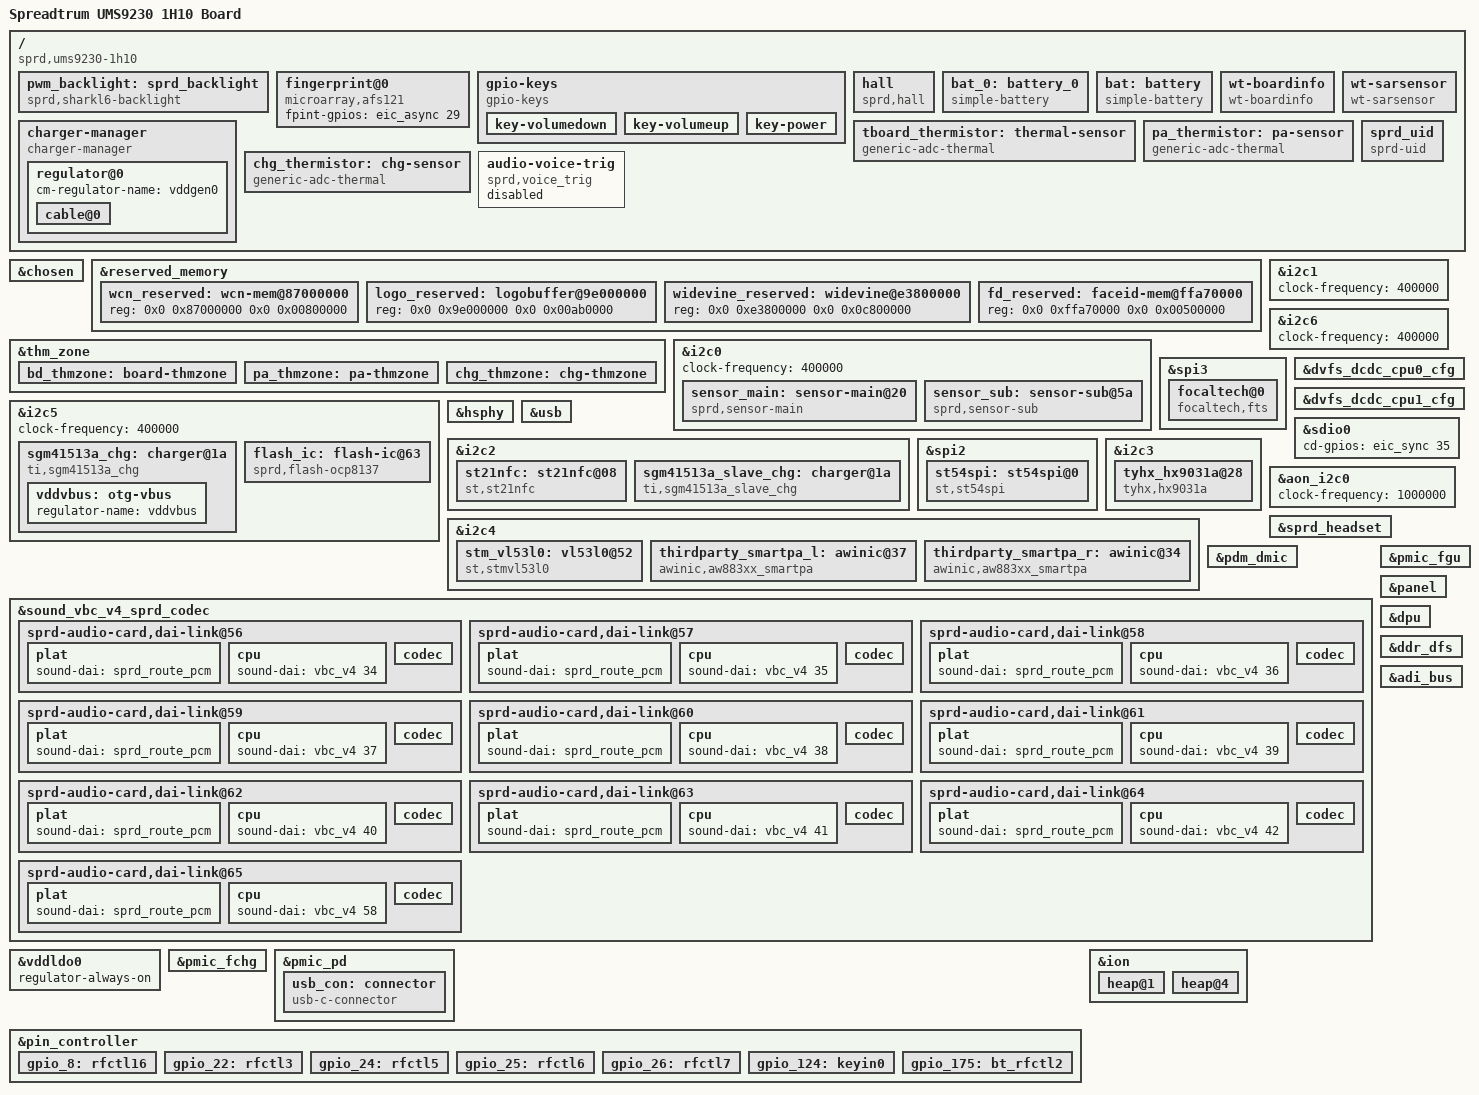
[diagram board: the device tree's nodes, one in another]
/dts-v1/;
/plugin/;
#include <dt-bindings/input/input.h>
#include <dt-bindings/gpio/gpio.h>
#include <dt-bindings/interrupt-controller/arm-gic.h>
#include <dt-bindings/clock/sprd,ums9230-clk.h>
#include <dt-bindings/mfd/sprd,sc2730-regs.h>
#include <dt-bindings/mfd/sprd,sc2730-mask.h>
#include <dt-bindings/usb/pd.h>
//#include "lcd/lcd_g40396_truly_mipi_fhd.dtsi"
//#include "lcd/lcd_dummy_mipi.dtsi"
#include "lcd/lcd_BL_TA4RUS07VOFMZTB_mipi_fhd.dtsi"
#include "TP/novatek-nt36xxx-spi.dtsi"
#include "ums9230-wcn.dtsi"

/ {

	model = "Spreadtrum UMS9230 1H10 Board";

	compatible = "sprd,ums9230-1h10";

	sprd,sc-id = "ums9230 1h10 1000";
	fragment {
		target-path = "/";
		__overlay__ {
			pwm_backlight: sprd_backlight {
				compatible = "sprd,sharkl6-backlight";
				pwms = <&pwms 2 40000>;
				pwm-names = "backlight";
				sprd,max-brightness-level = <924>;
				default-brightness-level = <262>;
				//sprd,brightness-scale = <1023>;
				brightness-levels = <
							              0   8   8   9  10  10 
                         11  12  13  13  14  15  16  17  18  19 
                         20  21  22  23  24  25  26  27  28  29 
                         30  32  33  34  35  37  38  39  41  42 
                         44  45  47  48  50  51  53  54  56  58 
                         59  61  63  64  66  68  70  71  73  75 
                         77  79  81  83  85  87  89  91  93  95 
                         97  99 102 104 106 108 111 113 115 118 
                        120 122 125 127 130 132 135 137 140 142 
                        145 147 150 153 155 158 161 164 167 169 
                        172 175 178 181 184 187 190 193 196 199 
                        202 205 208 211 214 218 221 224 227 231 
                        234 237 241 244 247 251 254 258 261 265 
                        268 272 275 279 283 286 290 294 297 301 
                        305 309 313 316 320 324 328 332 336 340 
                        344 348 352 356 360 364 369 373 377 381 
                        386 390 394 398 403 407 412 416 420 425 
                        429 434 438 443 448 452 457 461 466 471 
                        476 480 485 490 495 499 504 509 514 519 
                        524 529 534 539 544 549 554 559 565 570 
                        575 580 585 591 596 601 607 612 617 623 
                        628 634 639 645 650 656 661 667 672 678 
                        684 689 695 701 707 712 718 724 730 736 
                        742 748 754 760 766 772 778 784 790 796 
                        802 808 814 821 827 833 839 846 852 858 
                        865 871 877 884 890 897 903 910 917 924
				>;
			};

			fingerprint@0 {
				compatible = "microarray,afs121";
				fpint-gpios = <&eic_async 29 0>;
			};

			gpio-keys {
				compatible = "gpio-keys";

				key-volumedown {
					label = "Volume Down Key";
					linux,code = <KEY_VOLUMEDOWN>;
					gpios = <&pmic_eic 4 GPIO_ACTIVE_HIGH>;
					debounce-interval = <2>;
					wakeup-source;
				};

				key-volumeup {
					label = "Volume Up Key";
					linux,code = <KEY_VOLUMEUP>;
					gpios = <&ap_gpio 124 GPIO_ACTIVE_LOW>;					
					debounce-interval = <2>;
					wakeup-source;
				};

				key-power {
					label = "Power Key";
					linux,code = <KEY_POWER>;
					gpios = <&pmic_eic 1 GPIO_ACTIVE_LOW>;
					debounce-interval = <2>;
					wakeup-source;
				};
			};
			
            hall {
                    compatible = "sprd,hall";
                    gpio_det_level_pin = <&ap_gpio 122 GPIO_ACTIVE_LOW>;
                    status = "okay";
            };
			
			bat_0: battery_0 {
				compatible = "simple-battery";
				charge-full-design-microamp-hours = <8205000>;
				charge-term-current-microamp = <200000>;
				constant-charge-voltage-max-microvolt = <4432000>;
				fullbatt-voltage-offset-microvolt = <45000>;
				factory-internal-resistance-micro-ohms = <92000>;
				voltage-min-design-microvolt = <3450000>;
				fullbatt-voltage = <4340000>;
				fullbatt-current = <200000>;
				fullbatt-track-end-vol = <4345000>;
				fullbatt-track-end-cur = <130000>;
				first-calib-voltage = <3630000>;
				first-calib-capacity = <50>;

				ocv-capacity-celsius = <20>;
				ocv-capacity-table-0 = <4366000 100>, <4310000 95>, <4253000 90>,
							<4197000 85>, <4143000 80>, <4090000 75>,
							<4044000 70>, <3992000 65>, <3953000 60>,
							<3895000 55>, <3862000 50>, <3837000 45>,
							<3816000 40>, <3800000 35>, <3785000 30>,
							<3765000 25>, <3746000 20>, <3720000 15>,
							<3693000 10>, <3678000 5>, <3400000 0>;
				voltage-temp-table = <1095000 800>, <986000 850>, <879000 900>,
							  <755000 950>, <678000 1000>, <590000 1050>,
							  <510000 1100>, <440000 1150>, <378000 1200>,
							  <325000 1250>, <278000 1300>, <238000 1350>,
							  <204000 1400>, <175000 1450>, <150000 1500>,
							  <129000 1550>, <115000 1600>, <97000 1650>;
				capacity-temp-table = <25 100>, <10 100>, <(-10) 98>;
				resistance-temp-table = <25 100>, <10 131>, <(-10) 840>;

				charge-sdp-current-microamp = <510000 600000>;
				charge-dcp-current-microamp = <2100000 2100000>;
				charge-cdp-current-microamp = <2100000 2100000>;
				charge-unknown-current-microamp = <510000 600000>;
				charge-fchg-current-microamp = <4000000 2000000>;
				

				dcp-jeita-temp-table = <1000 1010 0 4400000>, <1150 1160 1600000 4400000>,
					<1450 1440 2100000 4400000>, <1550 1545 2100000 4100000>;
				sdp-jeita-temp-table = <1000 1010 0 4400000>, <1150 1160 510000 4400000>,
					<1450 1440 510000 4400000>, <1550 1545 510000 4100000>;
				cdp-jeita-temp-table = <1000 1010 0 4400000>, <1150 1160 1600000 4400000>,
					<1450 1440 2100000 4400000>, <1550 1545 2100000 4100000>;
				unknown-jeita-temp-table = <1000 1010 0 4400000>, <1150 1160 510000 4400000>,
					<1450 1440 510000 4400000>, <1550 1545 510000 4100000>;
                fchg-jeita-temp-table = <1000 1010 0 4400000>, <1150 1160 1600000 4400000>,
					<1450 1440 4000000 4400000>, <1550 1545 2000000 4100000>;
				force-jeita-status = <2>;
			};
			
			bat: battery {
				compatible = "simple-battery";
				charge-full-design-microamp-hours = <8101000>;
				charge-term-current-microamp = <200000>;
				constant-charge-voltage-max-microvolt = <4432000>;
				fullbatt-voltage-offset-microvolt = <45000>;
				factory-internal-resistance-micro-ohms = <125000>;
				voltage-min-design-microvolt = <3450000>;
				fullbatt-voltage = <4340000>;
				fullbatt-current = <200000>;
				fullbatt-track-end-vol = <4345000>;
				fullbatt-track-end-cur = <130000>;
				first-calib-voltage = <3630000>;
				first-calib-capacity = <50>;

				ocv-capacity-celsius = <20>;
				ocv-capacity-table-0 = <4363000 100>, <4297000 95>, <4236000 90>,
							<4178000 85>, <4123000 80>, <4071000 75>,
							<4016000 70>, <3973000 65>, <3932000 60>,
							<3877000 55>, <3842000 50>, <3817000 45>,
							<3798000 40>, <3782000 35>, <3770000 30>,
							<3756000 25>, <3738000 20>, <3716000 15>,
							<3687000 10>, <3669000 5>, <3400000 0>;
				voltage-temp-table = <1095000 800>, <986000 850>, <879000 900>,
							  <755000 950>, <678000 1000>, <590000 1050>,
							  <510000 1100>, <440000 1150>, <378000 1200>,
							  <325000 1250>, <278000 1300>, <238000 1350>,
							  <204000 1400>, <175000 1450>, <150000 1500>,
							  <129000 1550>, <115000 1600>, <97000 1650>;
				capacity-temp-table = <25 100>, <10 98>, <(-10) 93>;
				resistance-temp-table = <25 100>, <10 161>, <(-10) 766>;

				charge-sdp-current-microamp = <510000 600000>;
				charge-dcp-current-microamp = <2100000 2100000>;
				charge-cdp-current-microamp = <2100000 2100000>;
				charge-unknown-current-microamp = <510000 600000>;
				charge-fchg-current-microamp = <4000000 2000000>;
				

				dcp-jeita-temp-table = <1000 1010 0 4400000>, <1150 1160 1600000 4400000>,
					<1450 1440 2100000 4400000>, <1550 1545 2100000 4100000>;
				sdp-jeita-temp-table = <1000 1010 0 4400000>, <1150 1160 510000 4400000>,
					<1450 1440 510000 4400000>, <1550 1545 510000 4100000>;
				cdp-jeita-temp-table = <1000 1010 0 4400000>, <1150 1160 1600000 4400000>,
					<1450 1440 2100000 4400000>, <1550 1545 2100000 4100000>;
				unknown-jeita-temp-table = <1000 1010 0 4400000>, <1150 1160 510000 4400000>,
					<1450 1440 510000 4400000>, <1550 1545 510000 4100000>;
                fchg-jeita-temp-table = <1000 1010 0 4400000>, <1150 1160 1600000 4400000>,
					<1450 1440 4000000 4400000>, <1550 1545 2000000 4100000>;
				force-jeita-status = <2>;
			};
			
			
			wt-boardinfo{
				compatible = "wt-boardinfo";
				/*boardid1-gpio = <&ap_gpio 95 GPIO_ACTIVE_HIGH>;
				boardid2-gpio = <&ap_gpio 94 GPIO_ACTIVE_HIGH>;
				boardid3-gpio = <&ap_gpio 97 GPIO_ACTIVE_HIGH>;*/
			};
	
			wt-sarsensor{
				compatible = "wt-sarsensor";
			};
			
			charger-manager {
				compatible = "charger-manager";
				cm-name = "battery";
				cm-poll-mode = <2>;
				cm-poll-interval = <15000>;
				cm-battery-stat = <2>;

				cm-fullbatt-vchkdrop-ms = <30000>;
				cm-fullbatt-vchkdrop-volt = <60000>;
				cm-fullbatt-capacity = <100>;
				/*Charge pump target charge current*/
				cm-cp-taper-current = <1000000>;

				cm-num-chargers = <2>;
				cm-num-charge-pumps = <1>;
				cm-num-fast-chargers = <1>;
				cm-num-wireless-chargers = <1>;
				cm-num-wireless-charge-pump-converters = <1>;
				cm-chargers = "sgm41513a_charger","sgm41513a_slave_charger";
				cm-fast-chargers = "sc2730_fast_charger";
				cm-fuel-gauge = "sc27xx-fgu";

				/* in deci centigrade */
				cm-battery-cold = <0>;
				cm-battery-cold-in-minus;
				cm-battery-hot = <800>;
				cm-battery-temp-diff = <100>;

				/* Allow charging for 12hr */
				cm-charging-max = <43200000>;
				/* recovery charging after stop charging 45min */
				cm-discharging-max = <2700000>;

				/* the interval to feed charger watchdog */
				cm-wdt-interval = <60>;

				/* drop voltage in microVolts to allow shutdown */
				cm-shutdown-voltage = <3400000>;

				/* when 99% of the time is exceeded, it will be forced to 100% */
				cm-tickle-time-out = <1500>;

				/* how much time to allow capacity change */
				cm-one-cap-time = <30>;
				cm-thermal-zone = "chg-thmzone"; 
				/* when the safe charging voltage is exceeded, stop charging */
				cm-charge-voltage-max = <6220000>;
				cm-fast-charge-voltage-max = <10500000>;
				cm-flash-charge-voltage-max = <12000000>;
				cm-wireless-charge-voltage-max = <6220000>;
				cm-wireless-fast-charge-voltage-max = <12000000>;
				/* drop voltage in microVolts to restart charging */
				cm-charge-voltage-drop = <700000>;
				cm-fast-charge-voltage-drop = <700000>;
				cm-flash-charge-voltage-drop = <1000000>;
				cm-wireless-charge-voltage-drop = <700000>;
				cm-wireless-fast-charge-voltage-drop = <1000000>;

				cm-cap-remap-table = <1 4 3>, <4 10 2>, <97 99 2>, <99 100 2>;

				monitored-battery = <&bat_0 &bat>;

				regulator@0 {
					cm-regulator-name = "vddgen0";
					cable@0 {
						cm-cable-name = "USB";
						extcon = <&pmic_typec>;
					};
				};
			};

			tboard_thermistor: thermal-sensor {
				compatible = "generic-adc-thermal";
				#thermal-sensor-cells = <0>;
				io-channels = <&pmic_adc 1>;
				io-channel-names = "sensor-channel";
				temperature-lookup-table = <
					(-39742) 1131
					(-29777) 1110
					(-19480) 1074
					(-4679) 983
					10110 838
					24805 654
					44922 413
					54903 316
					64895 238
					74884 178
					84883 133
					94883 100
					104880 75
					114889 57
					124872 43 >;
			};

			pa_thermistor: pa-sensor {
				compatible = "generic-adc-thermal";
				#thermal-sensor-cells = <0>;
				io-channels = <&pmic_adc 2>;
				io-channel-names = "sensor-channel";
				temperature-lookup-table = <
					(-39742) 1131
					(-29777) 1110
					(-19480) 1074
					(-4679) 983
					10110 838
					24805 654
					44922 413
					54903 316
					64895 238
					74884 178
					84883 133
					94883 100
					104880 75
					114889 57
					124872 43 >;
			};

			chg_thermistor: chg-sensor {
				compatible = "generic-adc-thermal";
				#thermal-sensor-cells = <0>;
				io-channels = <&pmic_adc 4>;
				io-channel-names = "sensor-channel";
				temperature-lookup-table = <
					(-39742) 1131
					(-29777) 1110
					(-19480) 1074
					(-4679) 983
					10110 838
					24805 654
					44922 413
					54903 316
					64895 238
					74884 178
					84883 133
					94883 100
					104880 75
					114889 57
					124872 43 >;
			};

			audio-voice-trig {
				status = "disable";
				compatible = "sprd,voice_trig";
				//irq_gpio = <&ap_gpio 169 GPIO_ACTIVE_HIGH>;
			};

			sprd_uid {
				compatible = "sprd-uid";
				nvmem-cells = <&uid_start>, <&uid_end>;
				nvmem-cell-names = "uid_start", "uid_end";
			};

		};
	};
};

&chosen {
	bootargs_ext = "androidboot.hardware=ums9230_1h10 androidboot.dtbo_idx=0";
};

&reserved_memory {
	#address-cells = <2>;
	#size-cells = <2>;
	wcn_reserved: wcn-mem@87000000 {
		reg = <0x0 0x87000000 0x0 0x00800000>;
	};

	logo_reserved: logobuffer@9e000000{
		reg = <0x0 0x9e000000 0x0 0x00ab0000>;
	};
	
	widevine_reserved: widevine@e3800000 {
        reg = <0x0 0xe3800000 0x0 0x0c800000>;
    };

	fd_reserved: faceid-mem@ffa70000 {
		reg = <0x0 0xffa70000 0x0 0x00500000>;
	};
};

&thm_zone {
	bd_thmzone: board-thmzone {
		polling-delay-passive = <0>;
		polling-delay = <0>;
		thermal-sensors = <&tboard_thermistor>;
	};

	pa_thmzone: pa-thmzone {
		polling-delay-passive = <0>;
		polling-delay = <0>;
		thermal-sensors = <&pa_thermistor>;
	};

	chg_thmzone: chg-thmzone {
		polling-delay-passive = <0>;
		polling-delay = <0>;
		thermal-sensors = <&chg_thermistor>;
	};
};

&i2c0 {
	status = "okay";
	clock-frequency = <400000>;
	#address-cells = <1>;
	#size-cells = <0>;

	sensor_main: sensor-main@20 {
		compatible = "sprd,sensor-main";
		reg = <0x20>;
		clock-names = "clk_src","sensor_eb",
			"clk_96m","clk_76m8",
			"clk_48m","clk_26m";
		clocks = <&mm_clk CLK_SENSOR0>,<&mm_gate CLK_MM_SENSOR0_EB>,
				<&pll1 CLK_TWPLL_96M>,<&pll1 CLK_TWPLL_76M8>,
				<&pll1 CLK_TWPLL_48M>,<&ext_26m>;
		vddio-supply = <&vddcamio>;
		vddcama-supply = <&vddcama0>;
		vddcamd-supply = <&vddcamd0>;
		dvdd-gpios = <&ap_gpio 61 0>;
		vddcammot-supply = <&vddcammot>;
		reset-gpios = <&ap_gpio 44 0>;
		power-down-gpios = <&ap_gpio 46 0>;
		sprd,phyid = <0>;
		csi = <&csi0>;
		power-domains = <&mm_domain>;
	};

	sensor_sub: sensor-sub@5a {
		compatible = "sprd,sensor-sub";
		reg = <0x5a>;
		clock-names = "clk_src","sensor_eb",
			"clk_96m","clk_76m8",
			"clk_48m","clk_26m";
		clocks = <&mm_clk CLK_SENSOR1>,<&mm_gate CLK_MM_SENSOR1_EB>,
				<&pll1 CLK_TWPLL_96M>,<&pll1 CLK_TWPLL_76M8>,
				<&pll1 CLK_TWPLL_48M>,<&ext_26m>;
		vddio-supply = <&vddcamio>;
		vddcama-supply = <&vddcama0>;
		vddcamd-supply = <&vddcamd0>;
		dvdd-gpios = <&ap_gpio 61 0>;
		vddcammot-supply = <&vddcammot>;
		reset-gpios = <&ap_gpio 45 0>;
		power-down-gpios = <&ap_gpio 46 0>;
	/*	mipi-switch-en-gpios = <&ap_gpio 55 0>;*/
	/*	mipi-switch-mode-gpios = <&ap_gpio 8 0>;*/
		sprd,phyid = <1>;
		csi = <&csi0>;
		power-domains = <&mm_domain>;
	};
};

&i2c1 {
	status = "okay";
	clock-frequency = <400000>;
	#address-cells = <1>;
	#size-cells = <0>;

/*	sensor_main2: sensor-main2@20 {
		compatible = "sprd,sensor-main2";
		reg = <0x20>;
		clock-names = "clk_src","sensor_eb",
			"clk_96m","clk_76m8",
			"clk_48m","clk_26m";
		clocks = <&mm_clk CLK_SENSOR1>,<&mm_gate CLK_MM_SENSOR1_EB>,
				<&pll1 CLK_TWPLL_96M>,<&pll1 CLK_TWPLL_76M8>,
				<&pll1 CLK_TWPLL_48M>,<&ext_26m>;
		vddio-supply = <&vddcamio>;
		vddcama-supply = <&vddcama1>;
		vddcamd-supply = <&vddcamd0>;
		vddcammot-supply = <&vddcammot>;
		avdd-gpios = <&ap_gpio 33 0>;
		mot-gpios = <&ap_gpio 88 0>;
		reset-gpios = <&ap_gpio 41 0>;
		power-down-gpios = <&ap_gpio 40 0>;*/
	/*	mipi-switch-en-gpios = <&ap_gpio 55 0>;*/
	/*	mipi-switch-mode-gpios = <&ap_gpio 8 0>;*/
/*		sprd,phyid = <4>;
		csi = <&csi1>;
		power-domains = <&mm_domain>;
	};*/


};

&i2c5 {
	status = "okay";
	clock-frequency = <400000>;
	#address-cells = <1>;
	#size-cells = <0>;

	sgm41513a_chg: charger@1a {
		compatible = "ti,sgm41513a_chg";
		reg = <0x1a>;
		phys = <&hsphy>;
		monitored-battery = <&bat_0 &bat>;
		extcon = <&pmic_typec>, <&pmic_pd>;
		pd-extcon-enable;
		irq-gpio = <&ap_gpio 126 GPIO_ACTIVE_LOW>;
		vddvbus:otg-vbus {
			regulator-name = "vddvbus";
		};
	};

	

	flash_ic: flash-ic@63 {
		compatible = "sprd,flash-ocp8137";
		reg = <0x63>;
		sprd,flash-ic = <8137>;
		sprd,torch = <1>;
		sprd,preflash = <1>;
		sprd,highlight = <1>;
		sprd,torch-level = <128>;
		sprd,preflash-level = <128>;
		sprd,highlight-level = <128>;
		sprd,lvfm-enable = <1>;
		flash-torch-en-gpios = <&ap_gpio 139 0>;
		//flash-chip-en-gpios = <&ap_gpio 138 0>;
		flash-en-gpios = <&ap_gpio 32 0>;
		//flash-sync-gpios = <&ap_gpio 121 0>;
	};
};

&i2c6 {
	status = "okay";
	clock-frequency = <400000>;
	#address-cells = <1>;
	#size-cells = <0>;

/*	sensor_sub2: sensor-sub2@6e {
		compatible = "sprd,sensor-sub2";
		reg = <0x6e>;
		clock-names = "clk_src","sensor_eb",
			"clk_96m","clk_76m8",
			"clk_48m","clk_26m";
		clocks = <&mm_clk CLK_SENSOR2>,<&mm_gate CLK_MM_SENSOR2_EB>,
			<&pll1 CLK_TWPLL_96M>,<&pll1 CLK_TWPLL_76M8>,
			<&pll1 CLK_TWPLL_48M>,<&ext_26m>;
		vddio-supply = <&vddcamio>;
		avdd-gpios = <&ap_gpio 130 0>;
		vddcamd-supply = <&vddcamd1>;
		vddcammot-supply = <&vddcammot>;
		mot-gpios = <&ap_gpio 112 0>;
		reset-gpios = <&ap_gpio 114 0>;*/
	/*	power-down-gpios = <&ap_gpio 40 0>;*/
/*		sprd,phyid = <3>;
		csi = <&csi2>;
	};*/
};

&spi3 {
	status = "okay";
	#address-cells = <1>;
	#size-cells = <0>;

	focaltech@0 {
		compatible = "focaltech,fts";
		reg = <0x0>;
		focaltech,reset-gpio = <&ap_gpio 145 GPIO_ACTIVE_HIGH>;
		focaltech,irq-gpio = <&ap_gpio 144 GPIO_ACTIVE_HIGH>;
		focaltech,max-touch-number = <5>;
		focaltech,display-coords =  <0 0 1080 2400>;
		spi-max-frequency = <6000000>;
	};
};

&dvfs_dcdc_cpu0_cfg {
	pmic-type-num = <0>;
	slew-rate = <9375>; /* 9375uV/us */
	tuning-latency-us = <0>;
};

&dvfs_dcdc_cpu1_cfg {
	chnl-i2c-used;
	third-pmic-used;
	pmic-type-num = <2>;
	slew-rate = <4000>; /* 4000uV/us */
	tuning-latency-us = <0>;
};

&hsphy {
	vdd-supply = <&vddusb33>;
	extcon = <&extcon_gpio>;
	sprd,hsphy-device-eye-pattern = <0x04f3d1c0>;
	sprd,hsphy-host-eye-pattern = <0x04f3d1c0>;
	status = "okay";
};

&usb {
	extcon = <&extcon_gpio>, <&pmic_typec>;
	vbus-supply = <&vddvbus>;
	status = "okay";
};

&sdio0 {
	cd-gpios = <&eic_sync 35 GPIO_ACTIVE_HIGH>;
};

&i2c2 {
	status = "okay";
	#address-cells = <1>;
	#size-cells = <0>;
/*	sec-nfc@27 {
		compatible = "sec-nfc-1";
		reg = <0x27>;
		clock-names = "nfc_clk","source","enable";
		clocks = <&aon_clk CLK_AUX2>, <&ext_26m>, <&aonapb_gate CLK_AUX2_EB>;
		sec-nfc,ven-gpio = <&ap_gpio 63 0>;*/
		//sec-nfc,firm-gpio = <&ap_gpio 61 0>;
/*		sec-nfc,irq-gpio = <&ap_gpio 62 0>;
		sec-nfc,clk-req = <&ap_gpio 60 0>;
	};*/


	st21nfc: st21nfc@08 {
		compatible = "st,st21nfc";
		reg = <0x08>;
		interrupt-parent = <&ap_gpio>;
		interrupts = <112  0>;
		reset-gpios = <&ap_gpio 113 0x00>;
		irq-gpios = <&ap_gpio 112 0x00>;
		// pidle-gpios = <&ap_gpio 48 0x00>;
		clkreq-gpios = <&ap_gpio 88 0x00>;
		clkreq-dvt-gpios = <&ap_gpio 176 0x00>;
		clocks = <&aon_clk CLK_AUX2>, <&ext_26m>, <&aonapb_gate CLK_AUX2_EB>;
		clock-names = "nfc_ref_clk","source","enable";
		//st,clk_pinctrl;
		// i2c-retry = <0>;
		// status = "ok";
	};
	
	sgm41513a_slave_chg: charger@1a {
	    compatible = "ti,sgm41513a_slave_chg";
	    reg = <0x1a>;
	    phys = <&hsphy>;
	    monitored-battery = <&bat_0 &bat>;
	    extcon = <&pmic_typec>, <&pmic_pd>;
	    pd-extcon-enable;
        role-slave;
	    irq-gpio = <&ap_gpio 121 GPIO_ACTIVE_LOW>;
		enable-gpios = <&ap_gpio 115 0>;
	};
};

&spi2 {
	status = "okay";
	#address-cells = <1>;
	#size-cells = <0>;

	st54spi: st54spi@0 {
		compatible = "st,st54spi";
		reg = <0>;
		spi-max-frequency = <1000000>;
		/* gpio used as SE_PWR_REQ or SE_nRESET */
		gpio-power_nreset-std = <&ap_gpio 172 0>;
		/* Power management mode: none, ST54H (default), ST54J */
		power_mode = "ST54J";
		status = "okay";
	};
};

&i2c3 {
	status = "okay";
	#address-cells = <1>;
	#size-cells = <0>;

	tyhx_hx9031a@28 {
		compatible = "tyhx,hx9031a";
		reg = <0x28>;
		tyhx,irq-gpio = <&ap_gpio 96 0>;
		tyhx,channel-flag = <0x0f>;
	};
};

&i2c4 {
	status = "okay";
	#address-cells = <1>;
	#size-cells = <0>;

	stm_vl53l0: vl53l0@52 {
		compatible = "st,stmvl53l0";
		reg = <0x52>;
		reset_gpios = <168>;
		/*irq_gpios = <169>;
		interrupt-parent = <&ap_gpio>;
		interrupts = <169 IRQ_TYPE_LEVEL_LOW>;*/
	};
	
	
	/*AW883XX*/	
	thirdparty_smartpa_l: awinic@37 {
		compatible = "awinic,aw883xx_smartpa";
		reg = <0x37>;
		reset-gpio = <&ap_gpio 114 0>;
		irq-gpio = <&ap_gpio 62 0>;
		#sound-dai-cells = <0>;
		sound-channel = <0>;
		re-min = <1000>;
		re-max= <40000>;
		status = "okay";
	};

	thirdparty_smartpa_r: awinic@34 {
		compatible = "awinic,aw883xx_smartpa";
		reg = <0x34>;
		reset-gpio = <&ap_gpio 134 0>;
		irq-gpio = <&ap_gpio 169 0>;
		#sound-dai-cells = <0>;
		sound-channel = <1>;
		re-min = <1000>;
		re-max= <40000>;
		status = "okay";
	};	
	
};

&aon_i2c0 {
	status = "okay";
	clock-frequency = <1000000>;
};

&sprd_headset {
	status = "okay";
/*	extcon = <&pmic_typec>;
	mic-gpios = <&ap_gpio 175 GPIO_ACTIVE_HIGH>;
	lr-gpios = <&ap_gpio 174 GPIO_ACTIVE_HIGH>;
	sprd,3pole-adc-threshold = <112>;*/
};

&pdm_dmic {
	status = "okay";
};

&sound_vbc_v4_sprd_codec {
	status = "okay";



    /*
     * node 54 and node 55 (index 36 and 37) are reserved for
     * "ucp1301-spk2" and "ucp1301-rcv"
     * nodes from 56 to 67 (index from 38 to 49) are used by HIFI
     */

	/* 35: smart pa normal ap01 */
	sprd-audio-card,dai-link@56 {
		ignore-suspend = <1>;
		multi-codecs = <2>;
		link-name = "BE_NORMAL_AP01_HIFI";
		stream-name = "BE_ST_NORMAL_AP01_HIFI";
		no-pcm = <1>;
		dpcm-playback = <1>;
		be-id = <0>;
		dai-format = "i2s";
		plat {
			sound-dai = <&sprd_route_pcm>;
		};
		cpu {
			sound-dai = <&vbc_v4 34>;
		};
		codec {
			sound-dai = <&thirdparty_smartpa_l>,<&thirdparty_smartpa_r>;
		};
	};
	/* 36: smart pa normal ap23 */
	sprd-audio-card,dai-link@57 {
		ignore-suspend = <1>;
		multi-codecs = <2>;
		link-name = "BE_NORMAL_AP23_HIFI";
		stream-name = "BE_ST_NORMAL_AP23_HIFI";
		no-pcm = <1>;
		dpcm-playback = <1>;
		be-id = <0>;
		dai-format = "i2s";
		plat {
			sound-dai = <&sprd_route_pcm>;
		};
		cpu {
			sound-dai = <&vbc_v4 35>;
		};
		codec {
			sound-dai = <&thirdparty_smartpa_l>,<&thirdparty_smartpa_r>;
			
		};
	};
	/* 37: smart pa fast playback */
	sprd-audio-card,dai-link@58 {
		ignore-suspend = <1>;
		multi-codecs = <2>;
		link-name = "BE_FAST_P_HIFI";
		stream-name = "BE_ST_FAST_P_HIFI";
		no-pcm = <1>;
		dpcm-playback = <1>;
		be-id = <0>;
		dai-format = "i2s";
		plat {
			sound-dai = <&sprd_route_pcm>;
		};
		cpu {
			sound-dai = <&vbc_v4 36>;
		};
		codec {
			sound-dai = <&thirdparty_smartpa_l>,<&thirdparty_smartpa_r>;
		};
	};
	/* 38: smart pa offload */
	sprd-audio-card,dai-link@59 {
		ignore-suspend = <1>;
		multi-codecs = <2>;
		link-name = "BE_OFFLOAD_HIFI";
		stream-name = "BE_ST_OFFLOAD_HIFI";
		no-pcm = <1>;
		dpcm-playback = <1>;
		be-id = <0>;
		dai-format = "i2s";
		plat {
			sound-dai = <&sprd_route_pcm>;
		};
		cpu {
			sound-dai = <&vbc_v4 37>;
		};
		codec {
			sound-dai = <&thirdparty_smartpa_l>,<&thirdparty_smartpa_r>;
		};
	};
	/* 39: smart pa voice */
	sprd-audio-card,dai-link@60 {
		ignore-suspend = <1>;
		multi-codecs = <2>;
		link-name = "BE_VOICE_HIFI";
		stream-name = "BE_ST_VOICE_HIFI";
		no-pcm = <1>;
		dpcm-playback = <1>;
		be-id = <0>;
		dai-format = "i2s";
		plat {
			sound-dai = <&sprd_route_pcm>;
		};
		cpu {
			sound-dai = <&vbc_v4 38>;
		};
		codec {
			sound-dai = <&thirdparty_smartpa_l>,<&thirdparty_smartpa_r>;
		};
	};
	/* 40: smart pa voip */
	sprd-audio-card,dai-link@61 {
		ignore-suspend = <1>;
		multi-codecs = <2>;
		link-name = "BE_VOIP_HIFI";
		stream-name = "BE_DAI_ID_VOIP_HIFI";
		no-pcm = <1>;
		dpcm-playback = <1>;
		be-id = <0>;
		dai-format = "i2s";
		plat {
			sound-dai = <&sprd_route_pcm>;
		};
		cpu {
			sound-dai = <&vbc_v4 39>;
		};
		codec {
			sound-dai = <&thirdparty_smartpa_l>,<&thirdparty_smartpa_r>;
		};
	};
	/* 41: smart pa fm */
	sprd-audio-card,dai-link@62 {
		ignore-suspend = <1>;
		multi-codecs = <2>;
		link-name = "BE_FM_HIFI";
		stream-name = "BE_ST_FM_HIFI";
		no-pcm = <1>;
		dpcm-playback = <1>;
		be-id = <0>;
		dai-format = "i2s";
		plat {
			sound-dai = <&sprd_route_pcm>;
		};
		cpu {
			sound-dai = <&vbc_v4 40>;
		};
		codec {
			sound-dai = <&thirdparty_smartpa_l>,<&thirdparty_smartpa_r>;
		};
	};
	/* 42: smart pa loopback */
	sprd-audio-card,dai-link@63 {
		ignore-suspend = <1>;
		multi-codecs = <2>;
		link-name = "BE_LOOP_HIFI";
		stream-name = "BE_ST_LOOP_HIFI";
		no-pcm = <1>;
		dpcm-playback = <1>;
		be-id = <0>;
		dai-format = "i2s";
		plat {
			sound-dai = <&sprd_route_pcm>;
		};
		cpu {
			sound-dai = <&vbc_v4 41>;
		};
		codec {
			sound-dai = <&thirdparty_smartpa_l>,<&thirdparty_smartpa_r>;
		};
	};
	/* 43: smart pa fm dsp */
	sprd-audio-card,dai-link@64 {
		ignore-suspend = <1>;
		multi-codecs = <2>;
		link-name = "BE_FM_DSP_HIFI";
		stream-name = "BE_ST_FM_DSP_HIFI";
		no-pcm = <1>;
		dpcm-playback = <1>;
		be-id = <0>;
		dai-format = "i2s";
		plat {
			sound-dai = <&sprd_route_pcm>;
		};
		cpu {
			sound-dai = <&vbc_v4 42>;
		};
		codec {
			sound-dai = <&thirdparty_smartpa_l>,<&thirdparty_smartpa_r>;
		};
	};
	/* 44: smart pa mm */
	sprd-audio-card,dai-link@65 {
		ignore-suspend = <1>;
		multi-codecs = <2>;
		link-name = "BE_MM_HIFI";
		stream-name = "BE_ST_MM_HIFI";
		no-pcm = <1>;
		dpcm-playback = <1>;
		be-id = <0>;
		dai-format = "i2s";
		plat {
			sound-dai = <&sprd_route_pcm>;
		};
		cpu {
			sound-dai = <&vbc_v4 58>;
		};
		codec {
			sound-dai = <&thirdparty_smartpa_l>,<&thirdparty_smartpa_r>;
		};
	};

};

&vddldo0 {
	regulator-always-on;
};

&pmic_fgu {
	monitored-battery = <&bat_0 &bat>;
	sprd,calib-resistance-micro-ohms = <4850>;
	sprd,comp-resistance-mohm = <20>;

	fgu-capacity-track;
	phys = <&hsphy>;

	sprd,relax-counter-threshold = <580>;
	sprd,relax-current-threshold = <30>;
	sprd,capacity-sleep-calibration;

	sprd,capacity-boot-calibration;
	sprd,capacity-charge-cycle;
	sprd,basp;
};

&panel {
	sprd,backlight = <&pwm_backlight>;

	avdd-gpio = <&ap_gpio 135 GPIO_ACTIVE_HIGH>;
	avee-gpio = <&ap_gpio 136 GPIO_ACTIVE_HIGH>;
	reset-gpio = <&ap_gpio 50 GPIO_ACTIVE_HIGH>;
	lcm1v8en-gpio = <&ap_gpio 166 GPIO_ACTIVE_HIGH>;
};

&dpu {
	sprd,logo-memory = <&logo_reserved>;

	sprd,backlight = <&pwm_backlight>;
};

/*&lcd_g40396_truly_mipi_fhd {
	display-timings {
		g40396_truly_timing1: timing1 {
			clock-frequency = <192000000>;
			hactive = <720>;
			vactive = <1600>;
			hback-porch = <75>;
			hfront-porch = <75>;
			vback-porch = <32>;
			vfront-porch = <8>;
			hsync-len = <75>;
			vsync-len = <8>;
		};
	};
};*/

&pmic_fchg {
	status = "okay";
	sprd,input-voltage-microvolt = <5000000>;
	sprd,pd-fixed-max-microwatt = <18000000>;
	sprd,support-sfcp;
	sprd,support-pd-pps;
	phys = <&hsphy>;
};

&pmic_pd {
	status = "okay";
	usb_con: connector {
		compatible = "usb-c-connector";
		label = "USB-C";
		power-role = "dual";
		try-power-role = "sink";
		source-pdos = <PDO_FIXED(5000, 400, PDO_FIXED_USB_COMM)>;
		sink-pdos = <PDO_FIXED(5000, 3000, PDO_FIXED_USB_COMM)
			     PDO_PPS_APDO(3300, 11000, 3000)>;
		op-sink-microwatt = <10000000>;
	};
};

&ddr_dfs {
	  sprd-scene = "boost", "lcdon", "lcdoff", "camlow",
			"camhigh", "camveryhigh", "faceid", "top";
	  sprd-freq = <1333 768 256 1333 1333 0xbacd 1333 0xbacd>;
};

&pin_controller {
	pinctrl-names =
	/* rfctl16 ,rfctl3, rfctl5 */
	"gpio_8", "gpio_22", "gpio_24",
	/* rfctl6, rfctl7, keyin0 */
	"gpio_25", "gpio_26", "gpio_124",
	/* bt_rfctl2 */
	"gpio_175";
	pinctrl-0 = <&gpio_8>;
	pinctrl-1 = <&gpio_22>;
	pinctrl-2 = <&gpio_24>;
	pinctrl-3 = <&gpio_25>;
	pinctrl-4 = <&gpio_26>;
	pinctrl-5 = <&gpio_124>;
	pinctrl-6 = <&gpio_175>;

	gpio_8: rfctl16 {
		pins = "QOGIRL6_RFCTL16";
		function = "func4";
	};

	gpio_22: rfctl3 {
		pins = "QOGIRL6_RFCTL3";
		function = "func4";
	};

	gpio_24: rfctl5 {
		pins = "QOGIRL6_RFCTL5";
		function = "func4";
	};

	gpio_25: rfctl6 {
		pins = "QOGIRL6_RFCTL6";
		function = "func4";
	};

	gpio_26: rfctl7 {
		pins = "QOGIRL6_RFCTL7";
		function = "func4";
	};

	gpio_124: keyin0 {
		pins = "QOGIRL6_KEYIN0";
		function = "func4";
	};

	gpio_175: bt_rfctl2 {
		pins = "QOGIRL6_BT_RFCTL2";
		function = "func4";
	};
};

&ion {
	#address-cells = <1>;
	#size-cells = <0>;
	
	heap@1 {
        reg = <1>;
        label = "carveout_mm";
        type = <2>;
        memory-region = <&widevine_reserved>;
    };

	heap@4 {
		reg = <4>;
		label = "carveout_fd";
		type = <2>;
		memory-region = <&fd_reserved>;
	};
};

&adi_bus {
	sprd,hw-channels = <2 0x18cc>, <3 0x18cc>, <13 0x1854>, <15 0x1874>,
			<17 0x1844>, <19 0x1844>, <21 0x1864>, <30 0x1820>,
			<32 0x197c>, <33 0x1988>, <35 0x19b8>, <39 0x19ac>;
};
